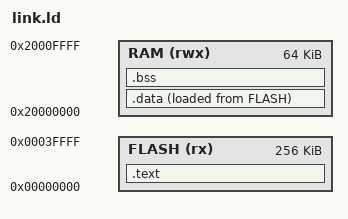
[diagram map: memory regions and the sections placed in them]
/* QEMU mps2-an385: code memory at 0x0, SRAM at 0x20000000 (we use 256 KiB and 64 KiB of them). */
MEMORY {
  FLASH (rx)  : ORIGIN = 0x00000000, LENGTH = 256K
  RAM   (rwx) : ORIGIN = 0x20000000, LENGTH = 64K
}
ENTRY(Reset_Handler)
SECTIONS {
  .text : { KEEP(*(.vectors)) *(.text*) *(.rodata*) . = ALIGN(4); } > FLASH
  .data : { _sdata = .; *(.data*) . = ALIGN(4); _edata = .; } > RAM AT > FLASH
  _sidata = LOADADDR(.data);
  .bss (NOLOAD) : { _sbss = .; *(.bss*) *(COMMON) . = ALIGN(4); _ebss = .; } > RAM
  _estack = ORIGIN(RAM) + LENGTH(RAM);
}
